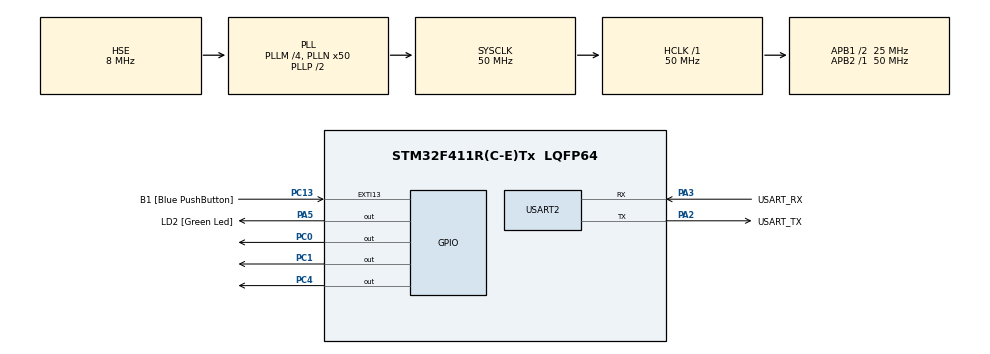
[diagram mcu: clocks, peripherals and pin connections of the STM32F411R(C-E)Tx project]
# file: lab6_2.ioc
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FREERTOS.Tasks01=defaultTask,24,128,StartDefaultTask,Default,NULL,Dynamic,NULL,NULL
FREERTOS.Timers01=tim01,Callback01,osTimerPeriodic,Default,NULL,Dynamic,NULL;tim02,Callback02,osTimerPeriodic,Default,NULL,Dynamic,NULL;tim03,Callback03,osTimerPeriodic,Default,NULL,Dynamic,NULL;tim04,Callback04,osTimerPeriodic,Default,NULL,Dynamic,NULL
FREERTOS.configENABLE_FPU=1
FREERTOS.configTICK_RATE_HZ=1000
Mcu.Family=STM32F4
Mcu.Name=STM32F411R(C-E)Tx
Mcu.Package=LQFP64
NVIC.PriorityGroup=NVIC_PRIORITYGROUP_4
NVIC.TIM4_IRQn=true\:15\:0\:false\:false\:true\:false\:false\:true\:true
NVIC.TimeBase=TIM4_IRQn
NVIC.TimeBaseIP=TIM4
PA13.GPIO_Label=TMS
PA13.Mode=Serial_Wire
PA13.Signal=SYS_JTMS-SWDIO
PA14.GPIO_Label=TCK
PA14.Mode=Serial_Wire
PA14.Signal=SYS_JTCK-SWCLK
PA2.GPIO_Label=USART_TX
PA2.Mode=Asynchronous
PA2.Signal=USART2_TX
PA3.GPIO_Label=USART_RX
PA3.Mode=Asynchronous
PA3.Signal=USART2_RX
PA5.GPIO_Label=LD2 [Green Led]
PA5.Signal=GPIO_Output
PB3.GPIO_Label=SWO
PB3.Signal=SYS_JTDO-SWO
PC0.Signal=GPIO_Output
PC1.Signal=GPIO_Output
PC13-ANTI_TAMP.GPIO_Label=B1 [Blue PushButton]
PC13-ANTI_TAMP.GPIO_ModeDefaultEXTI=GPIO_MODE_IT_FALLING
PC13-ANTI_TAMP.Signal=GPXTI13
PC14-OSC32_IN.Mode=LSE-External-Oscillator
PC14-OSC32_IN.Signal=RCC_OSC32_IN
PC15-OSC32_OUT.Mode=LSE-External-Oscillator
PC15-OSC32_OUT.Signal=RCC_OSC32_OUT
PC4.Signal=GPIO_Output
PH0\ -\ OSC_IN.Mode=HSE-External-Clock-Source
PH0\ -\ OSC_IN.Signal=RCC_OSC_IN
PH1\ -\ OSC_OUT.Mode=HSE-External-Clock-Source
PH1\ -\ OSC_OUT.Signal=RCC_OSC_OUT
ProjectManager.HeapSize=0x200
ProjectManager.StackSize=0x400
ProjectManager.TargetToolchain=STM32CubeIDE
RCC.48MHZClocksFreq_Value=25000000
RCC.AHBFreq_Value=50000000
RCC.APB1CLKDivider=RCC_HCLK_DIV2
RCC.APB1Freq_Value=25000000
RCC.APB1TimFreq_Value=50000000
RCC.APB2Freq_Value=50000000
RCC.APB2TimFreq_Value=50000000
RCC.CortexFreq_Value=50000000
RCC.FLatency-AdvancedSettings=FLASH_LATENCY_1
RCC.HCLKFreq_Value=50000000
RCC.HSE_VALUE=8000000
RCC.HSI_VALUE=16000000
RCC.PLLM=4
RCC.PLLN=50
RCC.PLLSourceVirtual=RCC_PLLSOURCE_HSE
RCC.SYSCLKFreq_VALUE=50000000
RCC.SYSCLKSource=RCC_SYSCLKSOURCE_PLLCLK
RCC.VCOOutputFreq_Value=100000000
USART2.VirtualMode=VM_ASYNC
VP_FREERTOS_VS_CMSIS_V2.Mode=CMSIS_V2
VP_SYS_VS_tim4.Mode=TIM4
board=NUCLEO-F411RE

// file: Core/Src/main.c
/* USER CODE BEGIN Header */
/**
  ******************************************************************************
  * @file           : main.c
  * @brief          : Main program body
  ******************************************************************************
  * @attention
  *
  * Copyright (c) 2023 STMicroelectronics.
  * All rights reserved.
  *
  * This software is licensed under terms that can be found in the LICENSE file
  * in the root directory of this software component.
  * If no LICENSE file comes with this software, it is provided AS-IS.
  *
  ******************************************************************************
  */
/* USER CODE END Header */
#include "main.h"
#include "cmsis_os.h"

UART_HandleTypeDef huart2;

/* Definitions for defaultTask */
osThreadId_t defaultTaskHandle;
const osThreadAttr_t defaultTask_attributes = {
        .name = "defaultTask",
        .stack_size = 128 * 4,
        .priority = (osPriority_t) osPriorityNormal,
};
/* Definitions for tim01 */
osTimerId_t tim01Handle;
const osTimerAttr_t tim01_attributes = {
        .name = "tim01"
};
/* Definitions for tim02 */
osTimerId_t tim02Handle;
const osTimerAttr_t tim02_attributes = {
        .name = "tim02"
};
/* Definitions for tim03 */
osTimerId_t tim03Handle;
const osTimerAttr_t tim03_attributes = {
        .name = "tim03"
};
/* Definitions for tim04 */
osTimerId_t tim04Handle;
const osTimerAttr_t tim04_attributes = {
        .name = "tim04"
};

void SystemClock_Config(void);

static void MX_GPIO_Init(void);

static void MX_USART2_UART_Init(void);

void StartDefaultTask(void *argument);

void Callback01(void *argument);

void Callback02(void *argument);

void Callback03(void *argument);

void Callback04(void *argument);

int main(void) {

    /* MCU Configuration--------------------------------------------------------*/

    /* Reset of all peripherals, Initializes the Flash interface and the Systick. */
    HAL_Init();

    /* Configure the system clock */
    SystemClock_Config();

    /* Initialize all configured peripherals */
    MX_GPIO_Init();
    MX_USART2_UART_Init();

    /* Init scheduler */
    osKernelInitialize();

    /* Create the timer(s) */
    /* creation of tim01 */
    tim01Handle = osTimerNew(Callback01, osTimerPeriodic, NULL, &tim01_attributes);

    /* creation of tim02 */
    tim02Handle = osTimerNew(Callback02, osTimerPeriodic, NULL, &tim02_attributes);

    /* creation of tim03 */
    tim03Handle = osTimerNew(Callback03, osTimerPeriodic, NULL, &tim03_attributes);

    /* creation of tim04 */
    tim04Handle = osTimerNew(Callback04, osTimerPeriodic, NULL, &tim04_attributes);

    /* USER CODE BEGIN RTOS_TIMERS */
    /* start timers, add new ones, ... */
    osTimerStart(tim01Handle, 50);
    osTimerStart(tim02Handle, 18);
    osTimerStart(tim03Handle, 128);
    osTimerStart(tim04Handle, 64);
    /* USER CODE END RTOS_TIMERS */

    /* Create the thread(s) */
    /* creation of defaultTask */
    defaultTaskHandle = osThreadNew(StartDefaultTask, NULL, &defaultTask_attributes);

    /* Start scheduler */
    osKernelStart();
    /* We should never get here as control is now taken by the scheduler */
    /* Infinite loop */
    while (1) {

    }
}

void SystemClock_Config(void) {
    RCC_OscInitTypeDef RCC_OscInitStruct = {0};
    RCC_ClkInitTypeDef RCC_ClkInitStruct = {0};

    /** Configure the main internal regulator output voltage
    */
    __HAL_RCC_PWR_CLK_ENABLE();
    __HAL_PWR_VOLTAGESCALING_CONFIG(PWR_REGULATOR_VOLTAGE_SCALE1);

    /** Initializes the RCC Oscillators according to the specified parameters
    * in the RCC_OscInitTypeDef structure.
    */
    RCC_OscInitStruct.OscillatorType = RCC_OSCILLATORTYPE_HSE;
    RCC_OscInitStruct.HSEState = RCC_HSE_BYPASS;
    RCC_OscInitStruct.PLL.PLLState = RCC_PLL_ON;
    RCC_OscInitStruct.PLL.PLLSource = RCC_PLLSOURCE_HSE;
    RCC_OscInitStruct.PLL.PLLM = 4;
    RCC_OscInitStruct.PLL.PLLN = 50;
    RCC_OscInitStruct.PLL.PLLP = RCC_PLLP_DIV2;
    RCC_OscInitStruct.PLL.PLLQ = 4;
    if (HAL_RCC_OscConfig(&RCC_OscInitStruct) != HAL_OK) {
        Error_Handler();
    }

    /** Initializes the CPU, AHB and APB buses clocks
    */
    RCC_ClkInitStruct.ClockType = RCC_CLOCKTYPE_HCLK | RCC_CLOCKTYPE_SYSCLK
                                  | RCC_CLOCKTYPE_PCLK1 | RCC_CLOCKTYPE_PCLK2;
    RCC_ClkInitStruct.SYSCLKSource = RCC_SYSCLKSOURCE_PLLCLK;
    RCC_ClkInitStruct.AHBCLKDivider = RCC_SYSCLK_DIV1;
    RCC_ClkInitStruct.APB1CLKDivider = RCC_HCLK_DIV2;
    RCC_ClkInitStruct.APB2CLKDivider = RCC_HCLK_DIV1;

    if (HAL_RCC_ClockConfig(&RCC_ClkInitStruct, FLASH_LATENCY_1) != HAL_OK) {
        Error_Handler();
    }
}

static void MX_USART2_UART_Init(void) {

    huart2.Instance = USART2;
    huart2.Init.BaudRate = 115200;
    huart2.Init.WordLength = UART_WORDLENGTH_8B;
    huart2.Init.StopBits = UART_STOPBITS_1;
    huart2.Init.Parity = UART_PARITY_NONE;
    huart2.Init.Mode = UART_MODE_TX_RX;
    huart2.Init.HwFlowCtl = UART_HWCONTROL_NONE;
    huart2.Init.OverSampling = UART_OVERSAMPLING_16;
    if (HAL_UART_Init(&huart2) != HAL_OK) {
        Error_Handler();
    }

}

static void MX_GPIO_Init(void) {
    GPIO_InitTypeDef GPIO_InitStruct = {0};

    /* GPIO Ports Clock Enable */
    __HAL_RCC_GPIOC_CLK_ENABLE();
    __HAL_RCC_GPIOH_CLK_ENABLE();
    __HAL_RCC_GPIOA_CLK_ENABLE();
    __HAL_RCC_GPIOB_CLK_ENABLE();

    /*Configure GPIO pin Output Level */
    HAL_GPIO_WritePin(GPIOC, GPIO_PIN_0 | GPIO_PIN_1 | GPIO_PIN_4, GPIO_PIN_RESET);

    /*Configure GPIO pin Output Level */
    HAL_GPIO_WritePin(LD2_GPIO_Port, LD2_Pin, GPIO_PIN_RESET);

    /*Configure GPIO pin : B1_Pin */
    GPIO_InitStruct.Pin = B1_Pin;
    GPIO_InitStruct.Mode = GPIO_MODE_IT_FALLING;
    GPIO_InitStruct.Pull = GPIO_NOPULL;
    HAL_GPIO_Init(B1_GPIO_Port, &GPIO_InitStruct);

    /*Configure GPIO pins : PC0 PC1 PC4 */
    GPIO_InitStruct.Pin = GPIO_PIN_0 | GPIO_PIN_1 | GPIO_PIN_4;
    GPIO_InitStruct.Mode = GPIO_MODE_OUTPUT_PP;
    GPIO_InitStruct.Pull = GPIO_NOPULL;
    GPIO_InitStruct.Speed = GPIO_SPEED_FREQ_LOW;
    HAL_GPIO_Init(GPIOC, &GPIO_InitStruct);

    /*Configure GPIO pin : LD2_Pin */
    GPIO_InitStruct.Pin = LD2_Pin;
    GPIO_InitStruct.Mode = GPIO_MODE_OUTPUT_PP;
    GPIO_InitStruct.Pull = GPIO_NOPULL;
    GPIO_InitStruct.Speed = GPIO_SPEED_FREQ_LOW;
    HAL_GPIO_Init(LD2_GPIO_Port, &GPIO_InitStruct);

}

void StartDefaultTask(void *argument) {
    for (;;) {
        osDelay(1);
    }
}

/* Callback01 function */
void Callback01(void *argument) {
    /* USER CODE BEGIN Callback01 */
    HAL_GPIO_TogglePin(GPIOA, GPIO_PIN_5);
    /* USER CODE END Callback01 */
}

/* Callback02 function */
void Callback02(void *argument) {
    /* USER CODE BEGIN Callback02 */
    HAL_GPIO_TogglePin(GPIOC, GPIO_PIN_0);
    /* USER CODE END Callback02 */
}

/* Callback03 function */
void Callback03(void *argument) {
    /* USER CODE BEGIN Callback03 */
    HAL_GPIO_TogglePin(GPIOC, GPIO_PIN_1);
    /* USER CODE END Callback03 */
}

/* Callback04 function */
void Callback04(void *argument) {
    /* USER CODE BEGIN Callback04 */
    HAL_GPIO_TogglePin(GPIOC, GPIO_PIN_4);
    /* USER CODE END Callback04 */
}

void HAL_TIM_PeriodElapsedCallback(TIM_HandleTypeDef *htim) {
    if (htim->Instance == TIM4) {
        HAL_IncTick();
    }
}

void Error_Handler(void) {
    __disable_irq();
    while (1) {
    }
}
